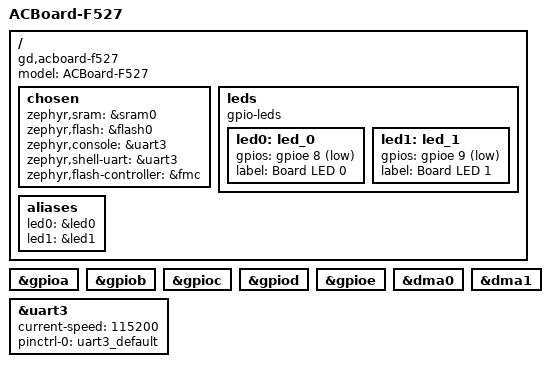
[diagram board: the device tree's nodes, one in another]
/*
 * Copyright (c) 2026
 * SPDX-License-Identifier: Apache-2.0
 */

/dts-v1/;

#include <arm/gd/gd32f5xx/gd32f527vxx.dtsi>
#include "acboard-pinctrl.dtsi"

/ {
	model = "ACBoard-F527";
	compatible = "gd,acboard-f527";

	chosen {
		zephyr,sram = &sram0;
		zephyr,flash = &flash0;
		zephyr,console = &uart3;
		zephyr,shell-uart = &uart3;
		zephyr,flash-controller = &fmc;
	};

	leds {
		compatible = "gpio-leds";
		led0: led_0 {
			gpios = <&gpioe 8 GPIO_ACTIVE_LOW>;
			label = "Board LED 0";
		};
		led1: led_1 {
			gpios = <&gpioe 9 GPIO_ACTIVE_LOW>;
			label = "Board LED 1";
		};
	};

	aliases {
		led0 = &led0;
		led1 = &led1;
	};
};

&gpioa {
	status = "okay";
};

&gpiob {
	status = "okay";
};

&gpioc {
	status = "okay";
};

&gpiod {
	status = "okay";
};

&gpioe {
	status = "okay";
};

&dma0 {
	status = "okay";
};

&dma1 {
	status = "okay";
};

/* Debug console, matching ACBoard GD32E513: TX PC10, RX PC11. */
&uart3 {
	status = "okay";
	current-speed = <115200>;
	pinctrl-0 = <&uart3_default>;
	pinctrl-names = "default";
};
